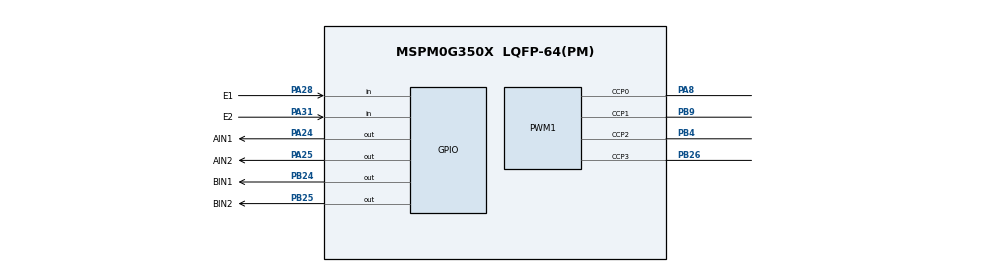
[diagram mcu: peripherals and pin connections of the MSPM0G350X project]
/**
 * @cliArgs --device "MSPM0G350X" --part "Default" --package "LQFP-64(PM)" --product "mspm0_sdk@2.11.00.07"
 * @versions {"tool":"1.26.2+4477"}
 */

/**
 * Import the modules used in this configuration.
 */
const GPIO   = scripting.addModule("/ti/driverlib/GPIO", {}, false);
const GPIO1  = GPIO.addInstance();
const GPIO2  = GPIO.addInstance();
const GPIO3  = GPIO.addInstance();
const PWM    = scripting.addModule("/ti/driverlib/PWM", {}, false);
const PWM1   = PWM.addInstance();
const SYSCTL = scripting.addModule("/ti/driverlib/SYSCTL");
const TIMER  = scripting.addModule("/ti/driverlib/TIMER", {}, false);
const TIMER1 = TIMER.addInstance();

/**
 * Write custom configuration values to the imported modules.
 */
GPIO1.$name                         = "AIN";
GPIO1.port                          = "PORTA";
GPIO1.associatedPins.create(2);
GPIO1.associatedPins[0].$name       = "AIN1";
GPIO1.associatedPins[0].assignedPin = "24";
GPIO1.associatedPins[0].ioStructure = "SD";
GPIO1.associatedPins[0].pin.$assign = "PA24";
GPIO1.associatedPins[1].$name       = "AIN2";
GPIO1.associatedPins[1].ioStructure = "SD";
GPIO1.associatedPins[1].assignedPin = "25";
GPIO1.associatedPins[1].pin.$assign = "PA25";

const Board = scripting.addModule("/ti/driverlib/Board", {}, false);

GPIO2.$name                         = "BIN";
GPIO2.port                          = "PORTB";
GPIO2.associatedPins.create(2);
GPIO2.associatedPins[0].$name       = "BIN1";
GPIO2.associatedPins[0].ioStructure = "SD";
GPIO2.associatedPins[0].assignedPin = "24";
GPIO2.associatedPins[0].pin.$assign = "PB24";
GPIO2.associatedPins[1].$name       = "BIN2";
GPIO2.associatedPins[1].assignedPin = "25";
GPIO2.associatedPins[1].ioStructure = "SD";
GPIO2.associatedPins[1].pin.$assign = "PB25";

GPIO3.$name                               = "Encoders";
GPIO3.port                                = "PORTA";
GPIO3.associatedPins.create(2);
GPIO3.associatedPins[0].$name             = "E1";
GPIO3.associatedPins[0].direction         = "INPUT";
GPIO3.associatedPins[0].interruptEn       = true;
GPIO3.associatedPins[0].interruptPriority = "0";
GPIO3.associatedPins[0].polarity          = "RISE";
GPIO3.associatedPins[0].assignedPin       = "28";
GPIO3.associatedPins[0].pin.$assign       = "PA28";
GPIO3.associatedPins[1].$name             = "E2";
GPIO3.associatedPins[1].direction         = "INPUT";
GPIO3.associatedPins[1].interruptEn       = true;
GPIO3.associatedPins[1].interruptPriority = "0";
GPIO3.associatedPins[1].polarity          = "RISE";
GPIO3.associatedPins[1].assignedPin       = "31";
GPIO3.associatedPins[1].pin.$assign       = "PA31";

PWM1.$name                      = "PWM_0";
PWM1.clockPrescale              = 2;
PWM1.timerStartTimer            = true;
PWM1.ccIndex                    = [0,1,2,3];
PWM1.PWM_CHANNEL_0.$name        = "ti_driverlib_pwm_PWMTimerCC0";
PWM1.PWM_CHANNEL_1.$name        = "ti_driverlib_pwm_PWMTimerCC1";
PWM1.ccp0PinConfig.$name        = "ti_driverlib_gpio_GPIOPinGeneric0";
PWM1.ccp1PinConfig.$name        = "ti_driverlib_gpio_GPIOPinGeneric1";
PWM1.peripheral.ccp0Pin.$assign = "PA8";
PWM1.peripheral.ccp1Pin.$assign = "PB9";
PWM1.peripheral.ccp2Pin.$assign = "PB4";
PWM1.peripheral.ccp3Pin.$assign = "PB26";
PWM1.PWM_CHANNEL_2.$name        = "ti_driverlib_pwm_PWMTimerCC2";
PWM1.PWM_CHANNEL_3.$name        = "ti_driverlib_pwm_PWMTimerCC3";
PWM1.ccp2PinConfig.$name        = "ti_driverlib_gpio_GPIOPinGeneric2";
PWM1.ccp3PinConfig.$name        = "ti_driverlib_gpio_GPIOPinGeneric3";

SYSCTL.forceDefaultClkConfig = true;

TIMER1.$name              = "PID_TIM";
TIMER1.timerClkDiv        = 8;
TIMER1.timerClkPrescale   = 100;
TIMER1.timerPeriod        = "20ms";
TIMER1.timerStartTimer    = true;
TIMER1.timerMode          = "PERIODIC";
TIMER1.interrupts         = ["ZERO"];
TIMER1.peripheral.$assign = "TIMG0";

/**
 * Pinmux solution for unlocked pins/peripherals. This ensures that minor changes to the automatic solver in a future
 * version of the tool will not impact the pinmux you originally saw.  These lines can be completely deleted in order to
 * re-solve from scratch.
 */
Board.peripheral.$suggestSolution          = "DEBUGSS";
Board.peripheral.swclkPin.$suggestSolution = "PA20";
Board.peripheral.swdioPin.$suggestSolution = "PA19";
PWM1.peripheral.$suggestSolution           = "TIMA0";
SYSCTL.peripheral.$suggestSolution         = "SYSCTL";
